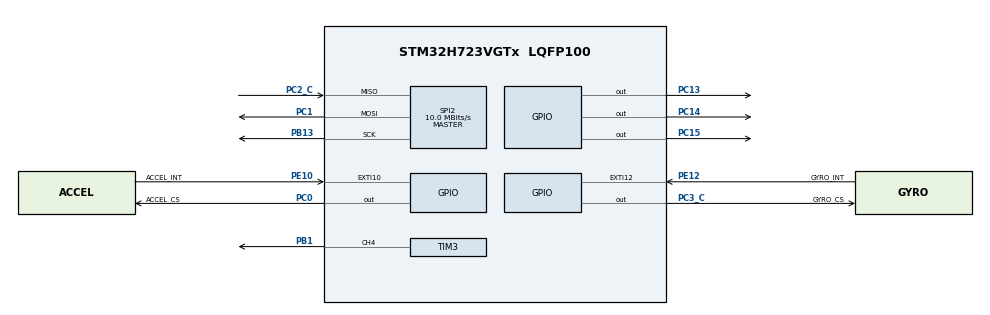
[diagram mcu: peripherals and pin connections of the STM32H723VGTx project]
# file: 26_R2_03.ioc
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CORTEX_M7.BaseAddress_Spec=0x24000000
CORTEX_M7.CPU_DCache=Enabled
CORTEX_M7.CPU_ICache=Enabled
CORTEX_M7.MPU_Control=MPU_HFNMI_PRIVDEF
CORTEX_M7.Size_Spec=MPU_REGION_SIZE_512KB
CORTEX_M7.TypeExtField_Spec=MPU_TEX_LEVEL1
CORTEX_M7.default_mode_Activation=1
FREERTOS.Tasks01=Start_INS_Task,2,2048,INS_Task,As weak,NULL,Static,Start_INS_TaskBuffer,Start_INS_TaskControlBlock
Mcu.Family=STM32H7
Mcu.Name=STM32H723VGTx
Mcu.Package=LQFP100
NVIC.PriorityGroup=NVIC_PRIORITYGROUP_4
NVIC.SPI2_IRQn=true\:5\:0\:false\:false\:true\:true\:true\:true\:true
NVIC.TIM2_IRQn=true\:15\:0\:false\:false\:true\:false\:false\:true\:true
NVIC.TimeBase=TIM2_IRQn
NVIC.TimeBaseIP=TIM2
PA13(JTMS/SWDIO).Mode=Serial_Wire
PA13(JTMS/SWDIO).Signal=DEBUG_JTMS-SWDIO
PA14(JTCK/SWCLK).Mode=Serial_Wire
PA14(JTCK/SWCLK).Signal=DEBUG_JTCK-SWCLK
PB1.Signal=S_TIM3_CH4
PB13.GPIO_Speed=GPIO_SPEED_FREQ_VERY_HIGH
PB13.Mode=Full_Duplex_Master
PB13.Signal=SPI2_SCK
PC0.GPIO_Label=ACCEL_CS
PC0.GPIO_Speed=GPIO_SPEED_FREQ_MEDIUM
PC0.PinState=GPIO_PIN_SET
PC0.Signal=GPIO_Output
PC1.GPIO_Speed=GPIO_SPEED_FREQ_VERY_HIGH
PC1.Mode=Full_Duplex_Master
PC1.Signal=SPI2_MOSI
PC13.Signal=GPIO_Output
PC14-OSC32_IN.Signal=GPIO_Output
PC15-OSC32_OUT.Signal=GPIO_Output
PC2_C.GPIO_Speed=GPIO_SPEED_FREQ_VERY_HIGH
PC2_C.Mode=Full_Duplex_Master
PC2_C.Signal=SPI2_MISO
PC3_C.GPIO_Label=GYRO_CS
PC3_C.GPIO_Speed=GPIO_SPEED_FREQ_MEDIUM
PC3_C.PinState=GPIO_PIN_SET
PC3_C.Signal=GPIO_Output
PE10.GPIO_Label=ACCEL_INT
PE10.Signal=GPXTI10
PE12.GPIO_Label=GYRO_INT
PE12.Signal=GPXTI12
PH0-OSC_IN.Mode=HSE-External-Oscillator
PH0-OSC_IN.Signal=RCC_OSC_IN
PH1-OSC_OUT.Mode=HSE-External-Oscillator
PH1-OSC_OUT.Signal=RCC_OSC_OUT
ProjectManager.HeapSize=0x200
ProjectManager.StackSize=0x400
ProjectManager.TargetToolchain=MDK-ARM V5.32
RCC.ADCFreq_Value=48375000
RCC.APB1Freq_Value=120000000
RCC.APB2Freq_Value=120000000
RCC.APB3Freq_Value=120000000
RCC.APB4Freq_Value=120000000
RCC.CortexFreq_Value=480000000
RCC.D1PPRE=RCC_APB3_DIV2
RCC.D2PPRE1=RCC_APB1_DIV2
RCC.D2PPRE2=RCC_APB2_DIV2
RCC.D3PPRE=RCC_APB4_DIV2
RCC.DIVM1=2
RCC.DIVM3=24
RCC.DIVN1=40
RCC.DIVN3=240
RCC.DIVP1=1
RCC.DIVP3=3
RCC.HCLKFreq_Value=240000000
RCC.HPRE=RCC_HCLK_DIV2
RCC.HSE_VALUE=24000000
RCC.PLLFRACN=0
RCC.PLLSourceVirtual=RCC_PLLSOURCE_HSE
RCC.SPI123CLockSelection=RCC_SPI123CLKSOURCE_PLL3
RCC.SYSCLKFreq_VALUE=480000000
RCC.SYSCLKSource=RCC_SYSCLKSOURCE_PLLCLK
RCC.USBFreq_Value=240000000
SH.S_TIM3_CH4.0=TIM3_CH4,PWM Generation4 CH4
SPI2.BaudRatePrescaler=SPI_BAUDRATEPRESCALER_8
SPI2.CLKPhase=SPI_PHASE_2EDGE
SPI2.CLKPolarity=SPI_POLARITY_HIGH
SPI2.CalculateBaudRate=10.0 MBits/s
SPI2.DataSize=SPI_DATASIZE_8BIT
SPI2.Direction=SPI_DIRECTION_2LINES
SPI2.Mode=SPI_MODE_MASTER
SPI2.VirtualType=VM_MASTER
STMicroelectronics.X-CUBE-ALGOBUILD.1.5.0.LibraryCcDSPOoLibraryJjDSPOoLibrary=true
TIM3.Channel-PWM\ Generation4\ CH4=TIM_CHANNEL_4
VP_FREERTOS_VS_CMSIS_V1.Mode=CMSIS_V1
VP_MEMORYMAP_VS_MEMORYMAP.Mode=CurAppReg
VP_STMicroelectronics.X-CUBE-ALGOBUILD_VS_DSPOoLibraryJjLibrary_1.5.0_1.5.0.Mode=DSPOoLibraryJjLibrary
VP_SYS_VS_tim2.Mode=TIM2
board=custom

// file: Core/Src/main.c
/* USER CODE BEGIN Header */
/**
  ******************************************************************************
  * @file           : main.c
  * @brief          : Main program body
  ******************************************************************************
  * @attention
  *
  * Copyright (c) 2026 STMicroelectronics.
  * All rights reserved.
  *
  * This software is licensed under terms that can be found in the LICENSE file
  * in the root directory of this software component.
  * If no LICENSE file comes with this software, it is provided AS-IS.
  *
  ******************************************************************************
  */
/* USER CODE END Header */
#include "main.h"
#include "cmsis_os.h"
#include "memorymap.h"
#include "spi.h"
#include "tim.h"
#include "gpio.h"

/* USER CODE BEGIN Includes */
#include "bsp_mcu.h"

/* USER CODE END Includes */

void SystemClock_Config(void);
static void MPU_Config(void);
void MX_FREERTOS_Init(void);

int main(void)
{

  /* MPU Configuration--------------------------------------------------------*/
  MPU_Config();

  /* Enable the CPU Cache */

  /* Enable I-Cache---------------------------------------------------------*/
  SCB_EnableICache();

  /* Enable D-Cache---------------------------------------------------------*/
  SCB_EnableDCache();

  /* MCU Configuration--------------------------------------------------------*/

  /* Reset of all peripherals, Initializes the Flash interface and the Systick. */
  HAL_Init();

  /* Configure the system clock */
  SystemClock_Config();

  /* Initialize all configured peripherals */
  MX_GPIO_Init();
  MX_SPI2_Init();
  MX_TIM3_Init();

  /* Call init function for freertos objects (in cmsis_os2.c) */
  MX_FREERTOS_Init();

  /* Start scheduler */
  osKernelStart();

  /* We should never get here as control is now taken by the scheduler */

  /* Infinite loop */
  while (1)
  {

  }
}

void SystemClock_Config(void)
{
  RCC_OscInitTypeDef RCC_OscInitStruct = {0};
  RCC_ClkInitTypeDef RCC_ClkInitStruct = {0};

  /** Supply configuration update enable
  */
  HAL_PWREx_ConfigSupply(PWR_LDO_SUPPLY);

  /** Configure the main internal regulator output voltage
  */
  __HAL_PWR_VOLTAGESCALING_CONFIG(PWR_REGULATOR_VOLTAGE_SCALE0);

  while(!__HAL_PWR_GET_FLAG(PWR_FLAG_VOSRDY)) {}

  /** Initializes the RCC Oscillators according to the specified parameters
  * in the RCC_OscInitTypeDef structure.
  */
  RCC_OscInitStruct.OscillatorType = RCC_OSCILLATORTYPE_HSE;
  RCC_OscInitStruct.HSEState = RCC_HSE_ON;
  RCC_OscInitStruct.PLL.PLLState = RCC_PLL_ON;
  RCC_OscInitStruct.PLL.PLLSource = RCC_PLLSOURCE_HSE;
  RCC_OscInitStruct.PLL.PLLM = 2;
  RCC_OscInitStruct.PLL.PLLN = 40;
  RCC_OscInitStruct.PLL.PLLP = 1;
  RCC_OscInitStruct.PLL.PLLQ = 2;
  RCC_OscInitStruct.PLL.PLLR = 2;
  RCC_OscInitStruct.PLL.PLLRGE = RCC_PLL1VCIRANGE_3;
  RCC_OscInitStruct.PLL.PLLVCOSEL = RCC_PLL1VCOWIDE;
  RCC_OscInitStruct.PLL.PLLFRACN = 0;
  if (HAL_RCC_OscConfig(&RCC_OscInitStruct) != HAL_OK)
  {
    Error_Handler();
  }

  /** Initializes the CPU, AHB and APB buses clocks
  */
  RCC_ClkInitStruct.ClockType = RCC_CLOCKTYPE_HCLK|RCC_CLOCKTYPE_SYSCLK
                              |RCC_CLOCKTYPE_PCLK1|RCC_CLOCKTYPE_PCLK2
                              |RCC_CLOCKTYPE_D3PCLK1|RCC_CLOCKTYPE_D1PCLK1;
  RCC_ClkInitStruct.SYSCLKSource = RCC_SYSCLKSOURCE_PLLCLK;
  RCC_ClkInitStruct.SYSCLKDivider = RCC_SYSCLK_DIV1;
  RCC_ClkInitStruct.AHBCLKDivider = RCC_HCLK_DIV2;
  RCC_ClkInitStruct.APB3CLKDivider = RCC_APB3_DIV2;
  RCC_ClkInitStruct.APB1CLKDivider = RCC_APB1_DIV2;
  RCC_ClkInitStruct.APB2CLKDivider = RCC_APB2_DIV2;
  RCC_ClkInitStruct.APB4CLKDivider = RCC_APB4_DIV2;

  if (HAL_RCC_ClockConfig(&RCC_ClkInitStruct, FLASH_LATENCY_3) != HAL_OK)
  {
    Error_Handler();
  }
}

 /* MPU Configuration */

void MPU_Config(void)
{
  MPU_Region_InitTypeDef MPU_InitStruct = {0};

  /* Disables the MPU */
  HAL_MPU_Disable();

  /** Initializes and configures the Region and the memory to be protected
  */
  MPU_InitStruct.Enable = MPU_REGION_ENABLE;
  MPU_InitStruct.Number = MPU_REGION_NUMBER0;
  MPU_InitStruct.BaseAddress = 0x24000000;
  MPU_InitStruct.Size = MPU_REGION_SIZE_512KB;
  MPU_InitStruct.SubRegionDisable = 0x87;
  MPU_InitStruct.TypeExtField = MPU_TEX_LEVEL1;
  MPU_InitStruct.AccessPermission = MPU_REGION_NO_ACCESS;
  MPU_InitStruct.DisableExec = MPU_INSTRUCTION_ACCESS_DISABLE;
  MPU_InitStruct.IsShareable = MPU_ACCESS_SHAREABLE;
  MPU_InitStruct.IsCacheable = MPU_ACCESS_NOT_CACHEABLE;
  MPU_InitStruct.IsBufferable = MPU_ACCESS_NOT_BUFFERABLE;

  HAL_MPU_ConfigRegion(&MPU_InitStruct);
  /* Enables the MPU */
  HAL_MPU_Enable(MPU_HFNMI_PRIVDEF);

}

void HAL_TIM_PeriodElapsedCallback(TIM_HandleTypeDef *htim)
{
  if (htim->Instance == TIM2)
  {
    HAL_IncTick();
  }
}

void Error_Handler(void)
{
  __disable_irq();
  while (1)
  {
  }
}

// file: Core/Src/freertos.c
/* USER CODE BEGIN Header */
/**
  ******************************************************************************
  * File Name          : freertos.c
  * Description        : Code for freertos applications
  ******************************************************************************
  * @attention
  *
  * Copyright (c) 2026 STMicroelectronics.
  * All rights reserved.
  *
  * This software is licensed under terms that can be found in the LICENSE file
  * in the root directory of this software component.
  * If no LICENSE file comes with this software, it is provided AS-IS.
  *
  ******************************************************************************
  */
/* USER CODE END Header */

#include "FreeRTOS.h"
#include "task.h"
#include "main.h"
#include "cmsis_os.h"

osThreadId Start_INS_TaskHandle;
uint32_t Start_INS_TaskBuffer[ 2048 ];
osStaticThreadDef_t Start_INS_TaskControlBlock;

void INS_Task(void const * argument);

void MX_FREERTOS_Init(void); /* (MISRA C 2004 rule 8.1) */

/* GetIdleTaskMemory prototype (linked to static allocation support) */
void vApplicationGetIdleTaskMemory( StaticTask_t **ppxIdleTaskTCBBuffer, StackType_t **ppxIdleTaskStackBuffer, uint32_t *pulIdleTaskStackSize );

/* USER CODE BEGIN GET_IDLE_TASK_MEMORY */
static StaticTask_t xIdleTaskTCBBuffer;
static StackType_t xIdleStack[configMINIMAL_STACK_SIZE];

void vApplicationGetIdleTaskMemory( StaticTask_t **ppxIdleTaskTCBBuffer, StackType_t **ppxIdleTaskStackBuffer, uint32_t *pulIdleTaskStackSize )
{
  *ppxIdleTaskTCBBuffer = &xIdleTaskTCBBuffer;
  *ppxIdleTaskStackBuffer = &xIdleStack[0];
  *pulIdleTaskStackSize = configMINIMAL_STACK_SIZE;
  /* place for user code */
}
/* USER CODE END GET_IDLE_TASK_MEMORY */

void MX_FREERTOS_Init(void) {

  /* Create the thread(s) */
  /* definition and creation of Start_INS_Task */
  osThreadStaticDef(Start_INS_Task, INS_Task, osPriorityHigh, 0, 2048, Start_INS_TaskBuffer, &Start_INS_TaskControlBlock);
  Start_INS_TaskHandle = osThreadCreate(osThread(Start_INS_Task), NULL);

}

__weak void INS_Task(void const * argument)
{
  for(;;)
  {
    osDelay(1);
  }
}
